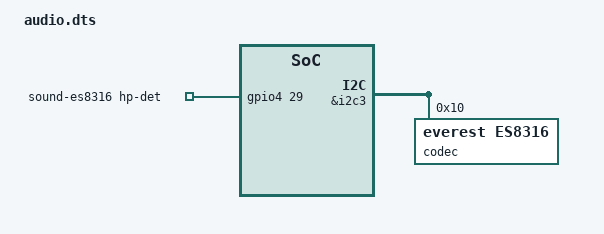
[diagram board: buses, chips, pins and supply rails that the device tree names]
	sound-hdmi {
		compatible = "fsl,imx-audio-hdmi";
		model = "audio-hdmi";
		audio-cpu = <&aud2htx>;
		hdmi-out;
		constraint-rate = <44100>,
				<88200>,
				<176400>,
				<32000>,
				<48000>,
				<96000>,
				<192000>;
		status = "okay";
	};

	sound-es8316 {
		compatible = "fsl,imx-audio-es8316";
		model = "es8316-audio";
		audio-cpu = <&sai3>;
		audio-codec = <&codec>;
		//audio-asrc = <&easrc>;
		format = "i2s";
		hp-det-gpio = <&gpio4 29 GPIO_ACTIVE_HIGH>;
	//	mic-det-gpio = <&gpio4 29 GPIO_ACTIVE_HIGH>;
		//jack-gpio = <&gpio4 29 GPIO_ACTIVE_HIGH>;
		//audio-widgets = 
			//"Microphone", "Mic Jack",
			//"Headphone", "Headphone Jack";

		audio-routing =
			"Mic Jack", "MIC2",
			//"MIC2", "Mic Jack",
			//"MIC2", "DMIC",
			"Headphone Jack", "HPOL",
			"Headphone Jack", "HPOR";
	};


&aud2htx {
	status = "okay";
};

&sai3 {
	pinctrl-names = "default";
	pinctrl-0 = <&pinctrl_sai3>;
	assigned-clocks = <&clk IMX8MP_CLK_SAI3>;
	assigned-clock-parents = <&clk IMX8MP_AUDIO_PLL1_OUT>;
	//assigned-clock-rates = <12288000>;
	assigned-clock-rates = <11289600>;
	//assigned-clock-rates = <12000000>;
	clocks = <&audio_blk_ctrl IMX8MP_CLK_AUDIO_BLK_CTRL_SAI3_IPG>, <&clk IMX8MP_CLK_DUMMY>,
		 <&audio_blk_ctrl IMX8MP_CLK_AUDIO_BLK_CTRL_SAI3_MCLK1>, <&clk IMX8MP_CLK_DUMMY>,
		 <&clk IMX8MP_CLK_DUMMY>;
	clock-names = "bus", "mclk0", "mclk1", "mclk2", "mclk3";
	fsl,sai-mclk-direction-output;
	status = "okay";
};

&i2c3 {
	codec: es8316@10 {
		compatible = "everest,es8316";
		reg = <0x10>;
		clocks = <&audio_blk_ctrl IMX8MP_CLK_AUDIO_BLK_CTRL_SAI3_MCLK1>;
		clock-names = "mclk";
	};
};

&iomuxc {
	pinctrl_sai3: sai3grp {
		fsl,pins = <
			MX8MP_IOMUXC_SAI3_TXFS__AUDIOMIX_SAI3_TX_SYNC	0xd6
			MX8MP_IOMUXC_SAI3_TXC__AUDIOMIX_SAI3_TX_BCLK	0xd6
			MX8MP_IOMUXC_SAI3_RXD__AUDIOMIX_SAI3_RX_DATA00	0xd6
			MX8MP_IOMUXC_SAI3_TXD__AUDIOMIX_SAI3_TX_DATA00	0xd6
			MX8MP_IOMUXC_SAI3_MCLK__AUDIOMIX_SAI3_MCLK	0xd6
			MX8MP_IOMUXC_SAI3_RXFS__AUDIOMIX_SAI3_RX_SYNC		0xd6
			MX8MP_IOMUXC_SAI3_RXC__GPIO4_IO29		0x16 //Hp Det
		>;
	};
};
